# Template register map
Vendor: VendorName Co.Ltd; Series: SeriesName; File version: 1.2
CPU: CM7 r0p1, little endian, MPU, FPU, 4 interrupt priority bits
Registers are 32-bit, read-write, no defined reset value unless marked. A register's access mark holds for its fields unless they carry their own. Offsets are from the block's base; [hi:lo] are bit positions; {n}, {i} and the like mark numbered series; 'fields as' and 'values as' point back to an identical list.

## SYSCON (part 1 of 2) — System Control
Base 0x40037000
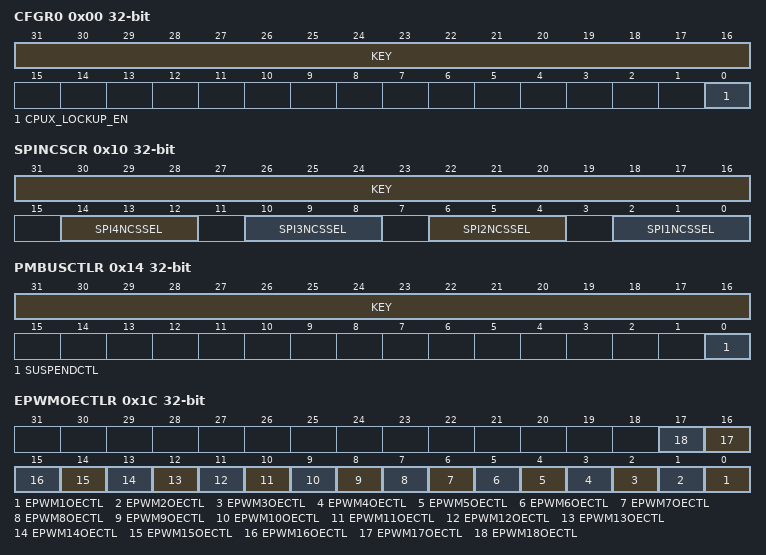
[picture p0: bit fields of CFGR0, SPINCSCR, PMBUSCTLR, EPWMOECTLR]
0x00 CFGR0 — SYSCON CPUx system configuration register 0
  [31:16] KEY wo — SYSCON KEY[15:0] bit: only when 0x5A69 is written can this register be written
  [0] CPUX_LOCKUP_EN — SYSCON CPUX_LOCKUP_EN bit: cortex-M7 CPUx lockup enable bit
0x10 SPINCSCR — SYSCON SPI SSN selection register
  [31:16] KEY wo — SYSCON KEY[15:0] bit: only when 0x5A69 is written can this register be written
  [4n-2:4n-4] SPI{n}NCSSEL (n=1..4) — SYSCON SPI{n}NCSSEL[2:0] bit: SPI{n} NCS signal input source select
0x14 PMBUSCTLR — SYSCON PMBUS control register
  [31:16] KEY wo — SYSCON KEY[15:0] bit: only when 0x5A69 is written at high position can this register be written
  [0] SUSPENDCTL — SYSCON SUSPENDCTL bit: PMBUS suspend control bit
0x1C EPWMOECTLR — SYSCON EPWM output control register
  [n-1] EPWM{n}OECTL (n=1..18) — SYSCON EPWM{n}OECTL bit: EPWM{n} reset output enable control bit
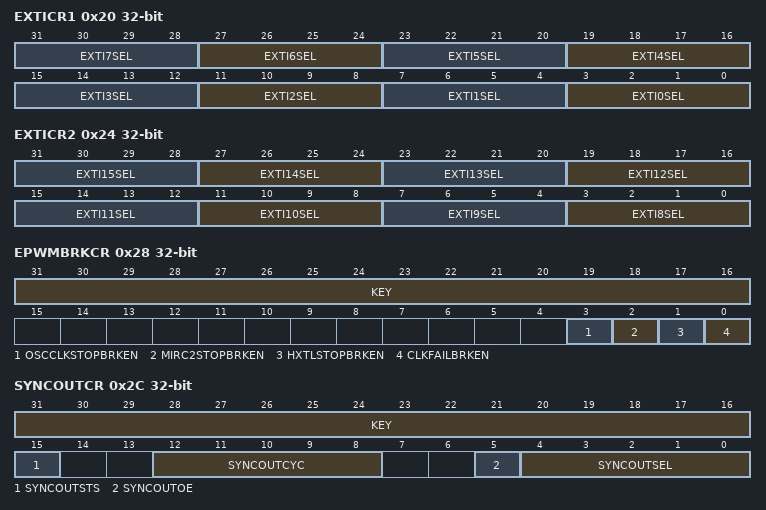
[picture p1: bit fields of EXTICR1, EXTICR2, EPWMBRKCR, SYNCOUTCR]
0x20 EXTICR1 — SYSCON EXTI control register 1
  [4n+3:4n] EXTI{n}SEL (n=0..7) — SYSCON EXTI{n}SEL[3:0] bit: EXTI{n} select
0x24 EXTICR2 — SYSCON EXTI control register 2
  [4n-29:4n-32] EXTI{n}SEL (n=8..15) — SYSCON EXTI{n}SEL[3:0] bit: EXTI{n} select
0x28 EPWMBRKCR — SYSCON EPWM clock fail brake control register
  [31:16] KEY wo — SYSCON KEY[15:0] bit: only when 0x5A69 is written at high position can this register be written
  [3] OSCCLKSTOPBRKEN — SYSCON OSCCLKSTOPBRKEN bit: OSC CLK STOP trigger epwm brake
  [2] MIRC2STOPBRKEN — SYSCON MIRC2STOPBRKEN bit: MIRCPU2 STOP trigger epwm brake
  [1] HXTLSTOPBRKEN — SYSCON HXTLSTOPBRKEN bit: HXTL STOP trigger epwm brake
  [0] CLKFAILBRKEN — SYSCON CLKFAILBRKEN bit: CLKFAIL trigger epwm brake
0x2C SYNCOUTCR — SYSCON SYNCOUT control register
  [31:16] KEY wo — SYSCON KEY[15:0] bit: only when 0x5A69 is written at high position can this register be written
  [15] SYNCOUTSTS ro — SYSCON SYNCOUTSTS bit: SYNCOUT widening status bit
  [12:8] SYNCOUTCYC — SYSCON SYNCOUTCYC[4:0] bit: SYNCOUT widening counting bit
  [5] SYNCOUTOE — SYSCON SYNCOUTOE bit: SYNCOUT output enable
  [4:0] SYNCOUTSEL — SYSCON SYNCOUTSEL[4:0] bit: SYNCOUT select bit
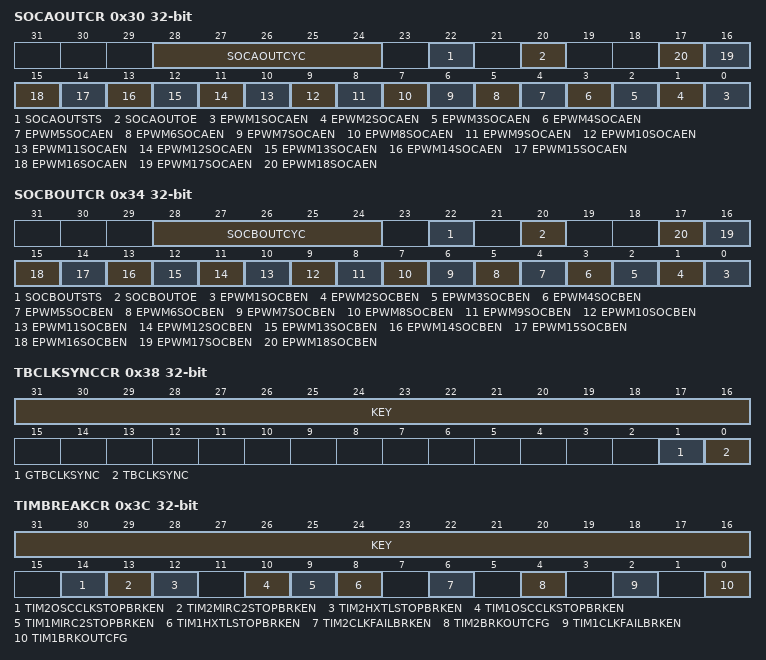
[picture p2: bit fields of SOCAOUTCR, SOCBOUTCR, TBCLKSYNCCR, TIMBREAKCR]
0x30 SOCAOUTCR — SYSCON SOACOUT control register
  [28:24] SOCAOUTCYC — SYSCON SOCAOUTCYC[4:0] bit: SOCAOUT widening counting bit
  [22] SOCAOUTSTS ro — SYSCON SOCAOUTSTS bit: SOCAOUT widening status bit
  [20] SOCAOUTOE — SYSCON SOCAOUTOE bit: ADCSOCA output enable
  [n-1] EPWM{n}SOCAEN (n=1..18) — SYSCON EPWM{n}SOCAEN bit: EPWM{n}SOCA enable bit
0x34 SOCBOUTCR — SYSCON SOCBOUT control register
  [28:24] SOCBOUTCYC — SYSCON SOCBOUTCYC[4:0] bit: SOCBOUT widening counting bit
  [22] SOCBOUTSTS ro — SYSCON SOCBOUTSTS bit: SOCBOUT widening status bit
  [20] SOCBOUTOE — SYSCON SOCBOUTOE bit: ADCSOCB output enable
  [n-1] EPWM{n}SOCBEN (n=1..18) — SYSCON EPWM{n}SOCBEN bit: EPWM{n}SOCB enable bit
0x38 TBCLKSYNCCR — SYSCON CPUx TIMER BASE clock sync control register
  [31:16] KEY wo — SYSCON KEY[15:0] bit: only when 0x5A69 is written at high position can this register be written
  [1] GTBCLKSYNC — SYSCON GTBCLKSYNC bit: global TBCLKSYNC enable bit
  [0] TBCLKSYNC — SYSCON TBCLKSYNC bit: TBCLKSYNC enable bit
0x3C TIMBREAKCR — SYSCON TIM brake control register
  [31:16] KEY wo — SYSCON KEY[15:0] bit: only when 0x5A69 is written at high position can this register be written
  [14] TIM2OSCCLKSTOPBRKEN — SYSCON TIM2OSCCLKSTOPBRKEN bit: OSCCLK STOP triggers TIM2 brake enable bit
  [13] TIM2MIRC2STOPBRKEN — SYSCON TIM2MIRC2STOPBRKEN bit: MIRC2 STOP triggers TIM2 brake enable bit
  [12] TIM2HXTLSTOPBRKEN — SYSCON TIM2HXTLSTOPBRKEN bit: HXTL STOP triggers TIM2 brake enable bit
  [10] TIM1OSCCLKSTOPBRKEN — SYSCON TIM1OSCCLKSTOPBRKEN bit: OSCCLK STOP triggers TIM1 brake enable bit
  [9] TIM1MIRC2STOPBRKEN — SYSCON TIM1MIRC2STOPBRKEN bit: MIRCPU2 STOP triggers TIM1 bake enable bit
  [8] TIM1HXTLSTOPBRKEN — SYSCON TIM1HXTLSTOPBRKEN bit: HXTL STOP triggers TIM1 brake enable bit
  [6] TIM2CLKFAILBRKEN — SYSCON TIM2CLKFAILBRKEN bit: clock fail triggers TIM2 brake enable bit
  [4] TIM2BRKOUTCFG — SYSCON TIM2BRKOUTCFG bit: TIM2 break output enable control bit
  [2] TIM1CLKFAILBRKEN — SYSCON TIM1CLKFAILBRKEN bit: clock fail triggers TIM1 brake enable bit
  [0] TIM1BRKOUTCFG — SYSCON TIM1BRKOUTCFG bit: TIM1 break output enable control bit
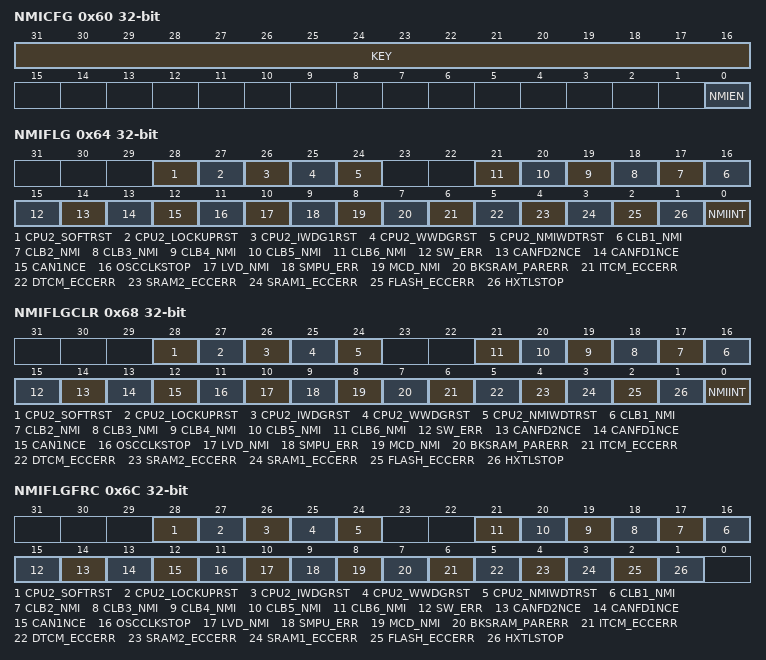
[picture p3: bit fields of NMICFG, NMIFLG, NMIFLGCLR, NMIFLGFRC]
0x60 NMICFG — SYSCON NMI configuration register
  [31:16] KEY wo — SYSCON KEY[15:0] bit: only when 0x5A69 is written at high position can this register be written
  [0] NMIEN — SYSCON NMIEN bit: NMI enable bit
0x64 NMIFLG ro — SYSCON NMI flag register
  [28] CPU2_SOFTRST — SYSCON CPU2_SOFTRST bit: CPU2 SOFT reset flag bit
  [27] CPU2_LOCKUPRST — SYSCON CPU2_LOCKUPRST bit: CPU2 LOCKUP reset flag bit
  [26] CPU2_IWDG1RST — SYSCON CPU2_IWDG1RST bit: CPU2 IWDG1 reset flag bit
  [25] CPU2_WWDGRST — SYSCON CPU2_WWDGRST bit: CPU2 WWDG reset flag bit
  [24] CPU2_NMIWDTRST — SYSCON CPU2_NMIWDTRST bit: CPU2 NMIWDT reset flag bit
  [n+15] CLB{n}_NMI (n=1..6) — SYSCON CLB{n}_NMI bit: CLB{n} NMI flag bit
  [15] SW_ERR — SYSCON SW_ERR bit: SW ERR flag bit
  [14] CANFD2NCE — SYSCON CANFD2NCE bit: CANFD2 NCE flag bit
  [13] CANFD1NCE — SYSCON CANFD1NCE bit: CANFD1 NCE flag bit
  [12] CAN1NCE — SYSCON CAN1NCE bit: CAN1 NCE flag bit
  [11] OSCCLKSTOP — SYSCON OSCCLKSTOP bit: OSCCLK STOP flag bit
  [10] LVD_NMI — SYSCON LVD_NMI bit: LVD NMI flag bit
  [9] SMPU_ERR — SYSCON SMPU_ERR bit: SMPU ECCERR flag bit
  [8] MCD_NMI — SYSCON MCD_NMI bit: MCD NMI flag bit
  [7] BKSRAM_PARERR — SYSCON BKSRAM_PARERR bit: BKSRAM PARERR flag bit
  [6] ITCM_ECCERR — SYSCON ITCM_ECCERR bit: ITCM ECCERR flag bit
  [5] DTCM_ECCERR — SYSCON DTCM_ECCERR bit: DTCM ECCERR flag bit
  [4] SRAM2_ECCERR — SYSCON SRAM2_ECCERR bit: SRAM2 ECCERR flag bit
  [3] SRAM1_ECCERR — SYSCON SRAM1_ECCERR bit: SRAM1 ECCERR flag bit
  [2] FLASH_ECCERR — SYSCON FLASH_ECCERR bit: FLASH ECCERR flag bit
  [1] HXTLSTOP — SYSCON HXTLSTOP bit: HXTL STOP flag bit
  [0] NMIINT — SYSCON NMIINT bit: NMI interrupt flag bit
0x68 NMIFLGCLR — SYSCON NMI flag clear register
  [28] CPU2_SOFTRST — SYSCON CPU2_SOFTRST bit: CPU2 SOFT reset flag clear bit
  [27] CPU2_LOCKUPRST — SYSCON CPU2_LOCKUPRST bit: CPU2 LOCKUP reset flag clear bit
  [26] CPU2_IWDGRST — SYSCON CPU2_IWDGRST bit: CPU2 IWDG reset flag clear bit
  [25] CPU2_WWDGRST — SYSCON CPU2_WWDGRST bit: CPU2 WWDG reset flag clear bit
  [24] CPU2_NMIWDTRST — SYSCON CPU2_NMIWDTRST bit: CPU2 NMIWDT reset flag clear bit
  [n+15] CLB{n}_NMI (n=1..6) — SYSCON CLB{n}_NMI bit: CLB{n} NMI flag clear bit
  [15] SW_ERR — SYSCON SW_ERR bit: SW ERR flag clear bit
  [14] CANFD2NCE — SYSCON CANFD2NCE bit: CANFD2 NCE flag clear bit
  [13] CANFD1NCE — SYSCON CANFD1NCE bit: CANFD1 NCE flag clear bit
  [12] CAN1NCE — SYSCON CAN1NCE bit: CAN1 NCE flag clear bit
  [11] OSCCLKSTOP — SYSCON OSCCLKSTOP bit: OSCCLK STOP flag clear bit
  [10] LVD_NMI — SYSCON LVD_NMI bit: LVD NMI flag clear bit
  [9] SMPU_ERR — SYSCON SMPU_ERR bit: SMPU ECCERR flag clear bit
  [8] MCD_NMI — SYSCON MCD_NMI bit: MCD NMI flag clear bit
  [7] BKSRAM_PARERR — SYSCON BKSRAM_PARERR bit: BKSRAM PARERR flag clear bit
  [6] ITCM_ECCERR — SYSCON ITCM_ECCERR bit: ITCM ECCERR flag clear bit
  [5] DTCM_ECCERR — SYSCON DTCM_ECCERR bit: DTCM ECCERR flag clear bit
  [4] SRAM2_ECCERR — SYSCON SRAM2_ECCERR bit: SRAM2 ECCERR flag clear bit
  [3] SRAM1_ECCERR — SYSCON SRAM1_ECCERR bit: SRAM1 ECCERR flag clear bit
  [2] FLASH_ECCERR — SYSCON FLASH_ECCERR bit: FLASH ECCERR flag clear bit
  [1] HXTLSTOP — SYSCON HXTLSTOP bit: HXTL STOP flag clear bit
  [0] NMIINT — SYSCON NMIINT bit: NMI interrupt flag clear bit
0x6C NMIFLGFRC — SYSCON NMI flag force register
  [28] CPU2_SOFTRST — SYSCON CPU2_SOFTRST bit: CPU2 SOFT reset flag force bit
  [27] CPU2_LOCKUPRST — SYSCON CPU2_LOCKUPRST bit: CPU2 LOCKUP reset flag force bit
  [26] CPU2_IWDGRST — SYSCON CPU2_IWDGRST bit: CPU2 IWDG reset flag force bit
  [25] CPU2_WWDGRST — SYSCON CPU2_WWDGRST bit: CPU2 WWDG reset flag force bit
  [24] CPU2_NMIWDTRST — SYSCON CPU2_NMIWDTRST bit: CPU2 NMIWDT reset flag force bit
  [n+15] CLB{n}_NMI (n=1..6) — SYSCON CLB{n}_NMI bit: CLB{n} NMI flag force bit
  [15] SW_ERR — SYSCON SW_ERR bit: SW ERR flag force bit
  [14] CANFD2NCE — SYSCON CANFD2NCE bit: CANFD2 NCE flag force bit
  [13] CANFD1NCE — SYSCON CANFD1NCE bit: CANFD1 NCE flag force bit
  [12] CAN1NCE — SYSCON CAN1NCE bit: CAN1 NCE flag force bit
  [11] OSCCLKSTOP — SYSCON OSCCLKSTOP bit: OSCCLK STOP flag force bit
  [10] LVD_NMI — SYSCON LVD_NMI bit: LVD NMI flag force bit
  [9] SMPU_ERR — SYSCON SMPU_ERR bit: SMPU ECCERR flag force bit
  [8] MCD_NMI — SYSCON MCD_NMI bit: MCD NMI flag force bit
  [7] BKSRAM_PARERR — SYSCON BKSRAM_PARERR bit: BKSRAM PARERR flag force bit
  [6] ITCM_ECCERR — SYSCON ITCM_ECCERR bit: ITCM ECCERR flag force bit
  [5] DTCM_ECCERR — SYSCON DTCM_ECCERR bit: DTCM ECCERR flag force bit
  [4] SRAM2_ECCERR — SYSCON SRAM2_ECCERR bit: SRAM2 ECCERR flag force bit
  [3] SRAM1_ECCERR — SYSCON SRAM1_ECCERR bit: SRAM1 ECCERR flag force bit
  [2] FLASH_ECCERR — SYSCON FLASH_ECCERR bit: FLASH ECCERR flag force bit
  [1] HXTLSTOP — SYSCON HXTLSTOP bit: HXTL STOP flag force bit
0x70 NMIWDGCNT ro — SYSCON NMIWDG counter register
  [15:0] NMIWDGCNT — SYSCON NMIWDGCNT[15:0] bit: NMIWDG counter
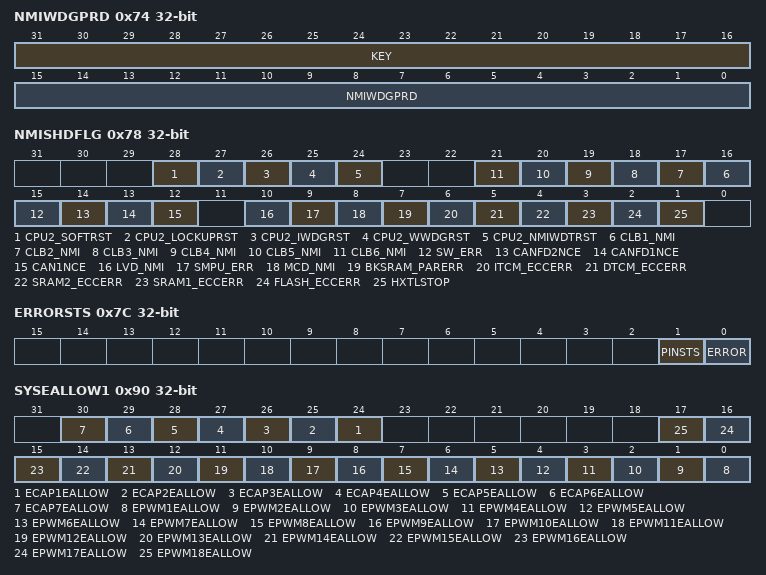
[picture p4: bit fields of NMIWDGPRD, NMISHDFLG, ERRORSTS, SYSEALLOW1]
0x74 NMIWDGPRD — SYSCON NMIWDG period register
  [31:16] KEY wo — SYSCON KEY[15:0] bit: only when 0x5A69 is written at high position can this register be written
  [15:0] NMIWDGPRD — SYSCON NMIWDGPRD[15:0] bit: NMIWDG period
0x78 NMISHDFLG ro — SYSCON NMI shadow flag register
  [28] CPU2_SOFTRST — SYSCON CPU2_SOFTRST bit: CPU2 SOFT reset shadow flag bit
  [27] CPU2_LOCKUPRST — SYSCON CPU2_LOCKUPRST bit: CPU2 LOCKUP reset shadow flag bit
  [26] CPU2_IWDGRST — SYSCON CPU2_IWDGRST bit: CPU2 IWDG reset shadow flag bit
  [25] CPU2_WWDGRST — SYSCON CPU2_WWDGRST bit: CPU2 WWDG reset shadow flag bit
  [24] CPU2_NMIWDTRST — SYSCON CPU2_NMIWDTRST bit: CPU2 NMIWDT reset shadow flag bit
  [n+15] CLB{n}_NMI (n=1..6) — SYSCON CLB{n}_NMI bit: CLB{n} NMI shadow flag bit
  [15] SW_ERR — SYSCON SW_ERR bit: SW ERR shadow flag bit
  [14] CANFD2NCE — SYSCON CANFD2NCE bit: CANFD2 NCE shadow flag bit
  [13] CANFD1NCE — SYSCON CANFD1NCE bit: CANFD1 NCE shadow flag bit
  [12] CAN1NCE — SYSCON CAN1NCE bit: CAN1 NCE shadow flag bit
  [10] LVD_NMI — SYSCON LVD_NMI bit: LVD NMI shadow flag bit
  [9] SMPU_ERR — SYSCON SMPU_ERR bit: SMPU ECCERR shadow flag bit
  [8] MCD_NMI — SYSCON MCD_NMI bit: MCD NMI shadow flag bit
  [7] BKSRAM_PARERR — SYSCON BKSRAM_PARERR bit: BKSRAM PARERR shadow flag bit
  [6] ITCM_ECCERR — SYSCON ITCM_ECCERR bit: ITCM ECCERR shadow flag bit
  [5] DTCM_ECCERR — SYSCON DTCM_ECCERR bit: DTCM ECCERR shadow flag bit
  [4] SRAM2_ECCERR — SYSCON SRAM2_ECCERR bit: SRAM2 ECCERR shadow flag bit
  [3] SRAM1_ECCERR — SYSCON SRAM1_ECCERR bit: SRAM1 ECCERR shadow flag bit
  [2] FLASH_ECCERR — SYSCON FLASH_ECCERR bit: FLASH ECCERR shadow flag bit
  [1] HXTLSTOP — SYSCON HXTLSTOP bit: HXTL STOP shadow flag bit
0x7C ERRORSTS ro — SYSCON error status register
  [1] PINSTS — SYSCON PINSTS bit: ERROR pin status bit
  [0] ERROR — SYSCON ERROR bit: ERROR status bit
0x80 ERRORSTSCLR — SYSCON error status clear register
  [0] ERROR — SYSCON ERROR bit: ERROR status clear bit
0x84 ERRORSTSFRC — SYSCON error status force register
  [0] ERROR — SYSCON ERROR bit: ERROR status force bit
0x88 ERRORCTL — SYSCON error status control register
  [0] ERRORPOL — SYSCON ERRORPOL bit: ERROR polarity select bit
0x8C ERRORLOCK — SYSCON error status lock register
  [0] ERRORCTL — SYSCON ERRORCTL bit: ERRORCTL register lock bit
0x90 SYSEALLOW1 — SYSCON system EALLOW register 1
  [n+23] ECAP{n}EALLOW (n=1..7) — SYSCON ECAP{n}EALLOW bit: ECAP{n} EALLOW write enable bit
  [n-1] EPWM{n}EALLOW (n=1..18) — SYSCON EPWM{n}EALLOW bit: EPWM{n} EALLOW write enable bit
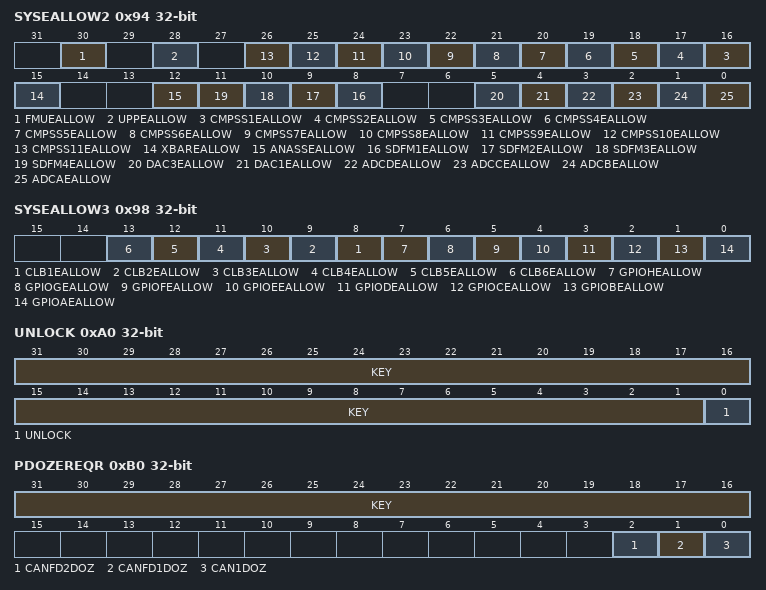
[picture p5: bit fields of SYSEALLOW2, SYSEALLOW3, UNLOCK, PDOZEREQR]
0x94 SYSEALLOW2 — SYSCON system EALLOW register 2
  [30] FMUEALLOW — SYSCON FMUEALLOW bit: FMU EALLOW write enable bit
  [28] UPPEALLOW — SYSCON UPPEALLOW bit: UPP EALLOW write enable bit
  [n+15] CMPSS{n}EALLOW (n=1..11) — SYSCON CMPSS{n}EALLOW bit: CMPSS{n} EALLOW write enable bit
  [15] XBAREALLOW — SYSCON XBAREALLOW bit: XBAR EALLOW write enable bit
  [12] ANASSEALLOW — SYSCON ANASSEALLOW bit: ANASS EALLOW write enable bit
  [n+7] SDFM{n}EALLOW (n=1..4) — SYSCON SDFM{n}EALLOW bit: SDFM{n} EALLOW write enable bit
  [5] DAC3EALLOW — SYSCON DAC3EALLOW bit: DAC3 EALLOW write enable bit
  [4] DAC1EALLOW — SYSCON DAC1EALLOW bit: DAC1 EALLOW write enable bit
  [3] ADCDEALLOW — SYSCON ADCDEALLOW bit: ADCD EALLOW write enable bit
  [2] ADCCEALLOW — SYSCON ADCCEALLOW bit: ADCC EALLOW write enable bit
  [1] ADCBEALLOW — SYSCON ADCBEALLOW bit: ADCB EALLOW write enable bit
  [0] ADCAEALLOW — SYSCON ADCAEALLOW bit: ADCA EALLOW write enable bit
0x98 SYSEALLOW3 — SYSCON system EALLOW register 3
  [n+7] CLB{n}EALLOW (n=1..6) — SYSCON CLB{n}EALLOW bit: CLB{n} EALLOW write enable bit
  [7] GPIOHEALLOW — SYSCON GPIOHEALLOW bit: GPIOH EALLOW write enable bit
  [6] GPIOGEALLOW — SYSCON GPIOGEALLOW bit: GPIOG EALLOW write enable bit
  [5] GPIOFEALLOW — SYSCON GPIOFEALLOW bit: GPIOF EALLOW write enable bit
  [4] GPIOEEALLOW — SYSCON GPIOEEALLOW bit: GPIOE EALLOW write enable bit
  [3] GPIODEALLOW — SYSCON GPIODEALLOW bit: GPIOD EALLOW write enable bit
  [2] GPIOCEALLOW — SYSCON GPIOCEALLOW bit: GPIOC EALLOW write enable bit
  [1] GPIOBEALLOW — SYSCON GPIOBEALLOW bit: GPIOB EALLOW write enable bit
  [0] GPIOAEALLOW — SYSCON GPIOAEALLOW bit: GPIOA EALLOW write enable bit
0xA0 UNLOCK — SYSCON lock bit for SYSCON register
  [31:1] KEY wo — SYSCON KEY[30:0] bit: only when 0x2AD5334C is written at high position can this register be written
  [0] UNLOCK — SYSCON UNLOCK bit: unlock protection enable bit
0xB0 PDOZEREQR — SYSCON peripheral module DOZE mode request register
  [31:16] KEY wo — SYSCON KEY[15:0] bit: only when 0x5A69 is written at high position can this register be written
  [2] CANFD2DOZ — SYSCON CANFD2DOZ bit: CANFD2 DOZE request
  [1] CANFD1DOZ — SYSCON CANFD1DOZ bit: CANFD1 DOZE request
  [0] CAN1DOZ — SYSCON CAN1DOZ bit: CAN1 DOZE request
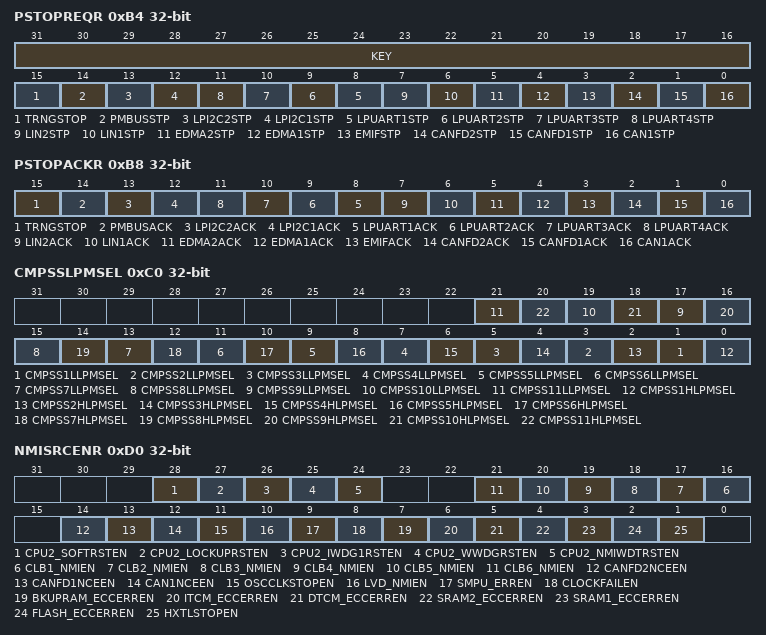
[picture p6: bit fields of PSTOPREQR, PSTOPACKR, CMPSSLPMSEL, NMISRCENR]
0xB4 PSTOPREQR — SYSCON peripheral module STOP mode request register
  [31:16] KEY wo — SYSCON KEY[15:0] bit: only when 0x5A69 is written at high position can this register be written
  [15] TRNGSTOP — SYSCON TRNGSTOP bit: TRNG STOP request
  [14] PMBUSSTP — SYSCON PMBUSSTP bit: PMBUS STOP request
  [13] LPI2C2STP — SYSCON LPI2C2STP bit: LPI2C2 STOP request
  [12] LPI2C1STP — SYSCON LPI2C1STP bit: LPI2C1 STOP request
  [n+7] LPUART{n}STP (n=1..4) — SYSCON LPUART{n}STP bit: LPUART{n} STOP request
  [7] LIN2STP — SYSCON LIN2STP bit: LIN2 STOP request
  [6] LIN1STP — SYSCON LIN1STP bit: LIN1 STOP request
  [5] EDMA2STP — SYSCON EDMA2STP bit: EDMA2 STOP request
  [4] EDMA1STP — SYSCON EDMA1STP bit: EDMA1 STOP request
  [3] EMIFSTP — SYSCON EMIFSTP bit: EMIF STOP request
  [2] CANFD2STP — SYSCON CANFD2STP bit: CANFD2 STOP request
  [1] CANFD1STP — SYSCON CANFD1STP bit: CANFD1 STOP request
  [0] CAN1STP — SYSCON CAN1STP bit: CAN1 STOP request
0xB8 PSTOPACKR ro — SYSCON peripheral module STOP mode acknowledge register
  [15] TRNGSTOP — SYSCON TRNGSTOP bit: TRNG STOP acknowledge bit
  [14] PMBUSACK — SYSCON PMBUSACK bit: PMBUS STOP acknowledge bit
  [13] LPI2C2ACK — SYSCON LPI2C2ACK bit: LPI2C2 STOP acknowledge bit
  [12] LPI2C1ACK — SYSCON LPI2C1ACK bit: LPI2C1 STOP acknowledge bit
  [n+7] LPUART{n}ACK (n=1..4) — SYSCON LPUART{n}ACK bit: LPUART{n} STOP acknowledge bit
  [7] LIN2ACK — SYSCON LIN2ACK bit: LIN2 STOP acknowledge bit
  [6] LIN1ACK — SYSCON LIN1ACK bit: LIN1 STOP acknowledge bit
  [5] EDMA2ACK — SYSCON EDMA2ACK bit: EDMA2 STOP acknowledge bit
  [4] EDMA1ACK — SYSCON EDMA1ACK bit: EDMA1 STOP acknowledge bit
  [3] EMIFACK — SYSCON EMIFACK bit: EMIF STOP acknowledge bit
  [2] CANFD2ACK — SYSCON CANFD2ACK bit: CANFD2 STOP acknowledge bit
  [1] CANFD1ACK — SYSCON CANFD1ACK bit: CANFD1 STOP acknowledge bit
  [0] CAN1ACK — SYSCON CAN1ACK bit: CAN1 STOP acknowledge bit
0xC0 CMPSSLPMSEL — SYSCON CMPSS low power mode wake up selecting register
  [2n-1] CMPSS{n}LLPMSEL (n=1..11) — SYSCON CMPSS{n}LLPMSEL bit: CMPSS{n}L and low power wake up and interruption circuit connection select
  [2n-2] CMPSS{n}HLPMSEL (n=1..11) — SYSCON CMPSS{n}HLPMSEL bit: CMPSS{n}H and low power wake up and interruption circuit connection select
0xD0 NMISRCENR — SYSCON NMI source enable register
  [28] CPU2_SOFTRSTEN — SYSCON CPU2_SOFTRSTEN bit: CPU2 SOFT reset enable bit
  [27] CPU2_LOCKUPRSTEN — SYSCON CPU2_LOCKUPRSTEN bit: CPU2 LOCKUP reset enable bit
  [26] CPU2_IWDG1RSTEN — SYSCON CPU2_IWDG1RSTEN bit: CPU2 IWDG1 reset enable bit
  [25] CPU2_WWDGRSTEN — SYSCON CPU2_WWDGRSTEN bit: CPU2 WWDG reset enable bit
  [24] CPU2_NMIWDTRSTEN — SYSCON CPU2_NMIWDTRSTEN bit: CPU2 NMIWDT reset enable bit
  [n+15] CLB{n}_NMIEN (n=1..6) — SYSCON CLB{n}_NMIEN bit: CLB{n} NMI enable bit
  [14] CANFD2NCEEN — SYSCON CANFD2NCEEN bit: CANFD2 NCE enable bit
  [13] CANFD1NCEEN — SYSCON CANFD1NCEEN bit: CANFD1 NCE enable bit
  [12] CAN1NCEEN — SYSCON CAN1NCEEN bit: CAN1 NCE enable bit
  [11] OSCCLKSTOPEN — SYSCON OSCCLKSTOPEN bit: OSCCLK STOP enable bit
  [10] LVD_NMIEN — SYSCON LVD_NMIEN bit: LVD NMI enable bit
  [9] SMPU_ERREN — SYSCON SMPU_ERREN bit: SMPU ECCERR enable bit
  [8] CLOCKFAILEN — SYSCON CLOCKFAILEN bit: CLOCKFAIL enable bit
  [7] BKUPRAM_ECCERREN — SYSCON BKUPRAM_ECCERREN bit: BKUPRAM ECCERR enable bit
  [6] ITCM_ECCERREN — SYSCON ITCM_ECCERREN bit: ITCM ECCERR enable bit
  [5] DTCM_ECCERREN — SYSCON DTCM_ECCERREN bit: DTCM ECCERR enable bit
  [4] SRAM2_ECCERREN — SYSCON SRAM2_ECCERREN bit: SRAM2 ECCERR enable bit
  [3] SRAM1_ECCERREN — SYSCON SRAM1_ECCERREN bit: SRAM1 ECCERR enable bit
  [2] FLASH_ECCERREN — SYSCON FLASH_ECCERREN bit: Flash ECCERR enable bit
  [1] HXTLSTOPEN — SYSCON HXTLSTOPEN bit: HXTL STOP enable bit
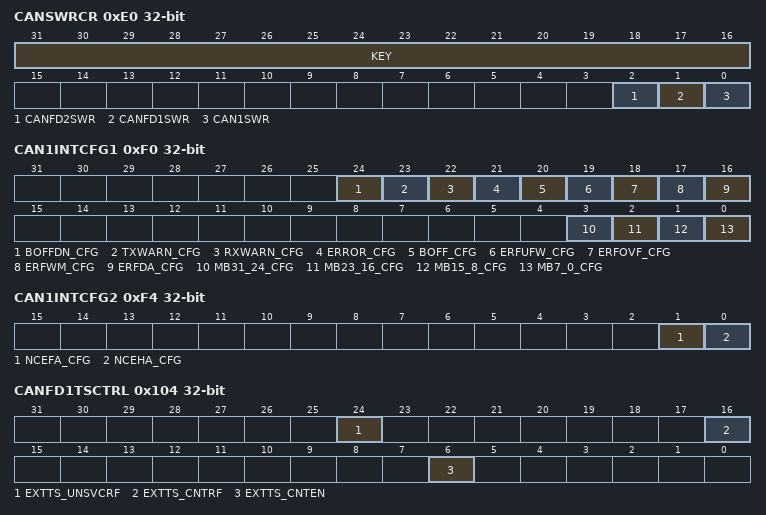
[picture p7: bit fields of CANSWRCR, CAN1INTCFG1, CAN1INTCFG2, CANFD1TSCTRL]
0xE0 CANSWRCR — SYSCON CAN software reset control register
  [31:16] KEY wo — SYSCON KEY[15:0] bit: only when 0x5A69 is written at high position can this register be written
  [2] CANFD2SWR — SYSCON CANFD2SWR bit: CANFD2 software reset
  [1] CANFD1SWR — SYSCON CANFD1SWR bit: CANFD1 software reset
  [0] CAN1SWR — SYSCON CAN1SWR bit: CAN1 software reset
0xF0 CAN1INTCFG1 — SYSCON CAN1 interrupt configuration register 1
  [24] BOFFDN_CFG — SYSCON BOFFDN_CFG bit: BUS OFF DONE interrupt configuration bit
  [23] TXWARN_CFG — SYSCON TXWARN_CFG bit: TX WARNING interrupt configuration bit
  [22] RXWARN_CFG — SYSCON RXWARN_CFG bit: RX WARNING interrupt configuration bit
  [21] ERROR_CFG — SYSCON ERROR_CFG bit: ERROR interrupt configuration bit
  [20] BOFF_CFG — SYSCON BOFF_CFG bit: BUS OFF interrupt configuration bit
  [19] ERFUFW_CFG — SYSCON ERFUFW_CFG bit: ERFUFW interrupt configuration bit
  [18] ERFOVF_CFG — SYSCON ERFOVF_CFG bit: ERFOVF interrupt configuration bit
  [17] ERFWM_CFG — SYSCON ERFWM_CFG bit: ERFWM interrupt configuration bit
  [16] ERFDA_CFG — SYSCON ERFDA_CFG bit: ERFDA interrupt configuration bit
  [3] MB31_24_CFG — SYSCON MB31_24_CFG bit: MB 31~24 interrupt configuration bit
  [2] MB23_16_CFG — SYSCON MB23_16_CFG bit: MB 23~16 interrupt configuration bit
  [1] MB15_8_CFG — SYSCON MB15_8_CFG bit: MB 15~8 interrupt configuration bit
  [0] MB7_0_CFG — SYSCON MB7_0_CFG bit: MB 7~0 interrupt configuration bit
0xF4 CAN1INTCFG2 — SYSCON CAN1 interrupt configuration register 2
  [1] NCEFA_CFG — SYSCON NCEFA_CFG bit: NCEFA interrupt configuration bit
  [0] NCEHA_CFG — SYSCON NCEHA_CFG bit: NCEHA interrupt configuration bit
0x104 CANFD1TSCTRL — SYSCON CANFD1 timestamp control register
  [24] EXTTS_UNSVCRF — SYSCON EXTTS_UNSVCRF bit: external timestamp count overflow interruption counting
  [16] EXTTS_CNTRF — SYSCON EXTTS_CNTRF bit: external timestamp counting clear bit
  [6] EXTTS_CNTEN — SYSCON EXTTS_CNTEN bit: external timestamp counting enable bit
0x10C CANFD1TSICR — SYSCON CANFD1 timestamp interruption clear register
  [0] EXTTS_OVFIC — SYSCON EXTTS_OVFIC bit: external timestamp overflow interruption clear bit
0x110 CANFD1TSIFR ro — SYSCON CANFD1 timestamp interruption flag register
  [0] EXTTS_OVFIF — SYSCON EXTTS_OVFIF bit: external timestamp overflow interruption flag bit
0x118 CANFD1TSIER — SYSCON CANFD1 timestamp interruption enable register
  [0] EXTTS_OVFIE — SYSCON EXTTS_OVFIE bit: external timestamp overflow interruption enable bit
0x124 CANFD1TSPRESC — SYSCON CANFD1 timestamp prescale register
  [23:0] EXTTS_PRESC — SYSCON EXTTS_PRESC[23:0] bit: external timestamp prescale counter
0x128 CANFD1TSUNSVCIC ro — SYSCON CANFD1 timestamp zero interruption counter register
  [4:0] EXTTS_UNSVC — SYSCON EXTTS_UNSVC[4:0] bit: external timestamp overflow interruption counter
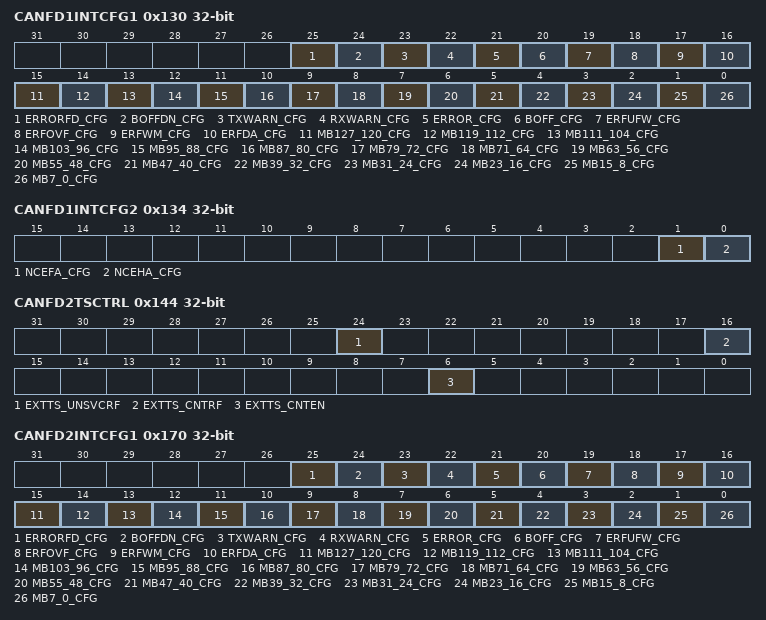
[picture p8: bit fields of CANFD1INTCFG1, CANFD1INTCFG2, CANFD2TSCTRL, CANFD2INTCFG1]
0x130 CANFD1INTCFG1 — SYSCON CANFD1 interrupt configuration register 1
  [25] ERRORFD_CFG — SYSCON ERRORFD_CFG bit: ERROR FD interrupt configuration bit
  [24] BOFFDN_CFG — SYSCON BOFFDN_CFG bit: BUS OFF DONE interrupt configuration bit
  [23] TXWARN_CFG — SYSCON TXWARN_CFG bit: TX WARNING interrupt configuration bit
  [22] RXWARN_CFG — SYSCON RXWARN_CFG bit: RX WARNING interrupt configuration bit
  [21] ERROR_CFG — SYSCON ERROR_CFG bit: ERROR interrupt configuration bit
  [20] BOFF_CFG — SYSCON BOFF_CFG bit: BUS OFF interrupt configuration bit
  [19] ERFUFW_CFG — SYSCON ERFUFW_CFG bit: ERFUFW interrupt configuration bit
  [18] ERFOVF_CFG — SYSCON ERFOVF_CFG bit: ERFOVF interrupt configuration bit
  [17] ERFWM_CFG — SYSCON ERFWM_CFG bit: ERFWM interrupt configuration bit
  [16] ERFDA_CFG — SYSCON ERFDA_CFG bit: ERFDA interrupt configuration bit
  [15] MB127_120_CFG — SYSCON MB127_120_CFG bit: MB 127~120 interrupt configuration bit
  [14] MB119_112_CFG — SYSCON MB119_112_CFG bit: MB 119~112 interrupt configuration bit
  [13] MB111_104_CFG — SYSCON MB111_104_CFG bit: MB 111~104 interrupt configuration bit
  [12] MB103_96_CFG — SYSCON MB103_96_CFG bit: MB 103~96 interrupt configuration bit
  [11] MB95_88_CFG — SYSCON MB95_88_CFG bit: MB 95~88 interrupt configuration bit
  [10] MB87_80_CFG — SYSCON MB87_80_CFG bit: MB 87~80 interrupt configuration bit
  [9] MB79_72_CFG — SYSCON MB79_72_CFG bit: MB 79~72 interrupt configuration bit
  [8] MB71_64_CFG — SYSCON MB71_64_CFG bit: MB 71~64 interrupt configuration bit
  [7] MB63_56_CFG — SYSCON MB63_56_CFG bit: MB 63~56 interrupt configuration bit
  [6] MB55_48_CFG — SYSCON MB55_48_CFG bit: MB 55~48 interrupt configuration bit
  [5] MB47_40_CFG — SYSCON MB47_40_CFG bit: MB 47~40 interrupt configuration bit
  [4] MB39_32_CFG — SYSCON MB39_32_CFG bit: MB 39~32 interrupt configuration bit
  [3] MB31_24_CFG — SYSCON MB31_24_CFG bit: MB 31~24 interrupt configuration bit
  [2] MB23_16_CFG — SYSCON MB23_16_CFG bit: MB 23~16 interrupt configuration bit
  [1] MB15_8_CFG — SYSCON MB15_8_CFG bit: MB 15~8 interrupt configuration bit
  [0] MB7_0_CFG — SYSCON MB7_0_CFG bit: MB 7~0 interrupt configuration bit
0x134 CANFD1INTCFG2 — SYSCON CANFD1 interrupt configuration register 2
  fields as CAN1INTCFG2
0x144 CANFD2TSCTRL — SYSCON CANFD2 timestamp control register
  fields as CANFD1TSCTRL
0x14C CANFD2TSICR — SYSCON CANFD2 timestamp interruption clear register
  fields as CANFD1TSICR
0x150 CANFD2TSIFR — SYSCON CANFD2 timestamp interruption flag register
  fields as CANFD1TSIFR
0x158 CANFD2TSIER — SYSCON CANFD2 timestamp interruption enable register
  fields as CANFD1TSIER
0x164 CANFD2TSPRESC — SYSCON CANFD2 timestamp prescale register
  fields as CANFD1TSPRESC
0x168 CANFD2TSUNSVCIC — SYSCON CANFD2 timestamp register
  fields as CANFD1TSUNSVCIC
0x170 CANFD2INTCFG1 — SYSCON CANFD2 interrupt configuration register 1
  fields as CANFD1INTCFG1
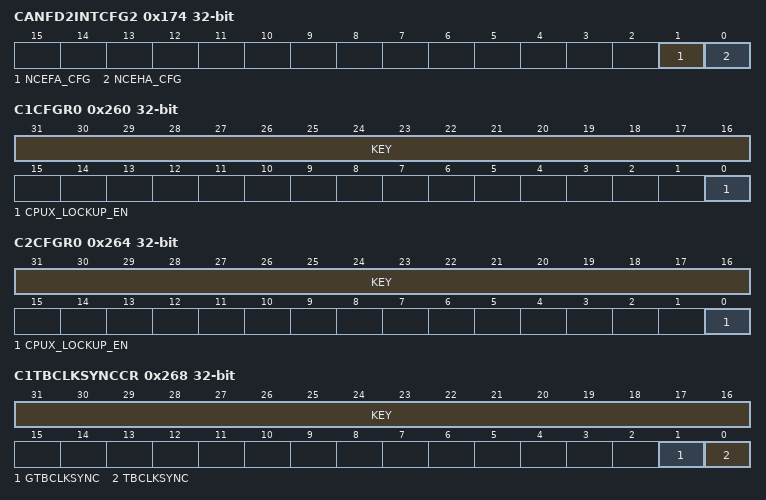
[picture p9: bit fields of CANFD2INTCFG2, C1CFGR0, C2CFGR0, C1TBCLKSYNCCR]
0x174 CANFD2INTCFG2 — SYSCON CANFD2 interrupt configuration register 2
  fields as CAN1INTCFG2
{0x1BC+4i} DMAMUX1REN{i} (i=1..4) — SYSCON DMAMUX1 request enable register {i}
  [31:0] DMAMUX1REN{i} — SYSCON DMAMUX1REN{i}[31:0] bit: DMAMUX1 number{32i-1}~{32i-32} request enable bit
0x1D0 DMAMUX1REN5 — SYSCON DMAMUX1 request enable register 5
  [13:0] DMAMUX1REN5 — SYSCON DMAMUX1REN5[13:0] bit: DMAMUX1 number141~128 request enable bit
{0x1DC+4i} DMAMUX2REN{i} (i=1..4) — SYSCON DMAMUX2 request enable register {i}
  [31:0] DMAMUX2REN{i} — SYSCON DMAMUX2REN{i}[31:0] bit: DMAMUX2 number{32i-1}~{32i-32} request enable bit
0x1F0 DMAMUX2REN5 — SYSCON DMAMUX2 request enable register 5
  [13:0] DMAMUX2REN5 — SYSCON DMAMUX2REN5[13:0] bit: DMAMUX2 number141~128 request enable bit
{0x1FC+4i} INTEN{i} (i=1..8) — SYSCON interrupt enable register {i}
  [31:0] INTEN{i} — SYSCON INTEN{i}[31:0] bit: number{32i-1}~{32i-32} interrupt enable bit
{0x21C+4i} C1INTEN{i} ro (i=1..8) — SYSCON CPU1 interrupt enable read only register {i}
  [31:0] INTEN{i} — SYSCON INTEN{i}[31:0] bit: CPU1 number{32i-1}~{32i-32} interrupt enable bit
{0x23C+4i} C2INTEN{i} ro (i=1..8) — SYSCON CPU2 interrupt enable read only register {i}
  [31:0] INTEN{i} — SYSCON INTEN{i}[31:0] bit: CPU2 number{32i-1}~{32i-32} interrupt enable bit
0x260 C1CFGR0 — SYSCON CPU1 system configuration read only register 0
  [31:16] KEY wo — SYSCON KEY[15:0] bit: only when 0x5A69 is written at high position can this register be written
  [0] CPUX_LOCKUP_EN ro — SYSCON CPUX_LOCKUP_EN bit: cortex-M7 CPU1 lockup function enable
0x264 C2CFGR0 — SYSCON CPU2 system configuration read only register 0
  [31:16] KEY wo — SYSCON KEY[15:0] bit: only when 0x5A69 is written at high position can this register be written
  [0] CPUX_LOCKUP_EN ro — SYSCON CPUX_LOCKUP_EN bit: cortex-M7 CPU2 lockup function enable
0x268 C1TBCLKSYNCCR — SYSCON CPU1 TIMER BASE clock sync control read only register
  [31:16] KEY wo — SYSCON KEY[15:0] bit: only when 0x5A69 is written at high position can this register be written
  [1] GTBCLKSYNC ro — SYSCON GTBCLKSYNC bit: CPU1 global TBCLKSYNC enable bit
  [0] TBCLKSYNC ro — SYSCON TBCLKSYNC bit: CPU1 TBCLKSYNC enable bit
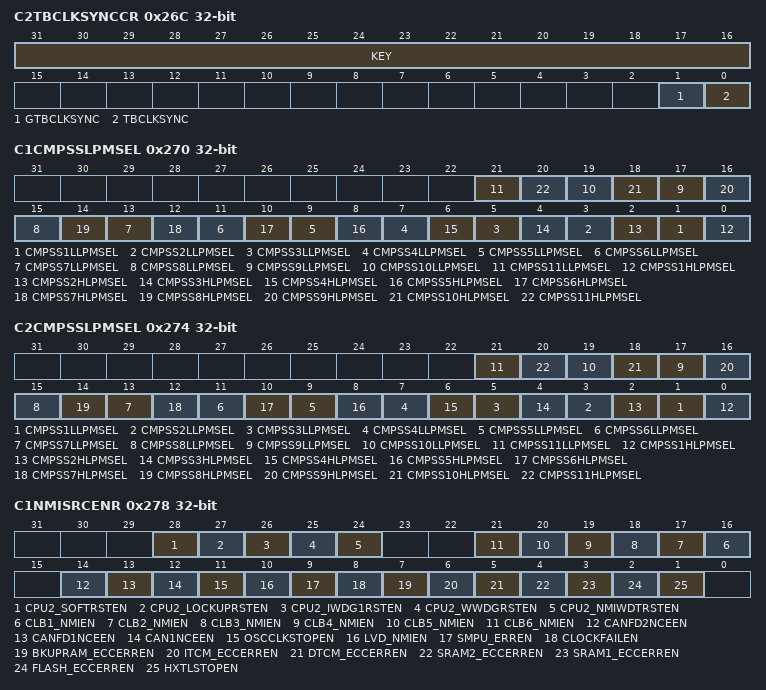
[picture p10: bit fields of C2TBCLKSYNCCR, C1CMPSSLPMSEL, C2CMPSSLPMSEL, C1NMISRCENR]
0x26C C2TBCLKSYNCCR — SYSCON CPU2 TIMER BASE clock sync control read only register
  [31:16] KEY wo — SYSCON KEY[15:0] bit: only when 0x5A69 is written at high position can this register be written
  [1] GTBCLKSYNC ro — SYSCON GTBCLKSYNC bit: CPU2 global TBCLKSYNC enable bit
  [0] TBCLKSYNC ro — SYSCON TBCLKSYNC bit: CPU2 TBCLKSYNC enable bit
0x270 C1CMPSSLPMSEL ro — SYSCON CPU1 CMPSS low power mode wake up or interrupt selecting read only register
  [2n-1] CMPSS{n}LLPMSEL (n=1..11) — SYSCON CMPSS{n}LLPMSEL bit: CPU1 CMPSS{n}L and low power wake up and interruption circuit connection select
  [2n-2] CMPSS{n}HLPMSEL (n=1..11) — SYSCON CMPSS{n}HLPMSEL bit: CPU1 CMPSS{n}H and low power wake up and interruption circuit connection select
0x274 C2CMPSSLPMSEL ro — SYSCON CPU2 CMPSS low power mode wake up or interrupt selecting read only register
  [2n-1] CMPSS{n}LLPMSEL (n=1..11) — SYSCON CMPSS{n}LLPMSEL bit: CPU2 CMPSS{n}L and low power wake up and interruption circuit connection select
  [2n-2] CMPSS{n}HLPMSEL (n=1..11) — SYSCON CMPSS{n}HLPMSEL bit: CPU2 CMPSS{n}H and low power wake up and interruption circuit connection select
0x278 C1NMISRCENR ro — SYSCON CPU1 NMI source enable read only register
  [28] CPU2_SOFTRSTEN — SYSCON CPU2_SOFTRSTEN bit: CPU2 SOFT reset enable bit of CPU1
  [27] CPU2_LOCKUPRSTEN — SYSCON CPU2_LOCKUPRSTEN bit: CPU2 LOCKUP reset enable bit of CPU1
  [26] CPU2_IWDG1RSTEN — SYSCON CPU2_IWDG1RSTEN bit: CPU2 IWDG1 reset enable bit of CPU1
  [25] CPU2_WWDGRSTEN — SYSCON CPU2_WWDGRSTEN bit: CPU2 WWDG reset enable bit of CPU1
  [24] CPU2_NMIWDTRSTEN — SYSCON CPU2_NMIWDTRSTEN bit: CPU2 NMIWDT reset enable bit of CPU1
  [n+15] CLB{n}_NMIEN (n=1..6) — SYSCON CLB{n}_NMIEN bit: CLB{n} NMI enable bit of CPU1
  [14] CANFD2NCEEN — SYSCON CANFD2NCEEN bit: CANFD2 NCE enable bit of CPU1
  [13] CANFD1NCEEN — SYSCON CANFD1NCEEN bit: CANFD1 NCE enable bit of CPU1
  [12] CAN1NCEEN — SYSCON CAN1NCEEN bit: CAN1 NCE enable bit of CPU1
  [11] OSCCLKSTOPEN — SYSCON OSCCLKSTOPEN bit: OSCCLK STOP enable bit of CPU1
  [10] LVD_NMIEN — SYSCON LVD_NMIEN bit: LVD NMI enable bit of CPU1
  [9] SMPU_ERREN — SYSCON SMPU_ERREN bit: SMPU ECCERR enable bit of CPU1
  [8] CLOCKFAILEN — SYSCON CLOCKFAILEN bit: CLOCKFAIL enable bit of CPU1
  [7] BKUPRAM_ECCERREN — SYSCON BKUPRAM_ECCERREN bit: BKUPRAM ECCERR enable bit of CPU1
  [6] ITCM_ECCERREN — SYSCON ITCM_ECCERREN bit: ITCM ECCERR enable bit of CPU1
  [5] DTCM_ECCERREN — SYSCON DTCM_ECCERREN bit: DTCM ECCERR enable bit of CPU1
  [4] SRAM2_ECCERREN — SYSCON SRAM2_ECCERREN bit: SRAM2 ECCERR enable bit of CPU1
  [3] SRAM1_ECCERREN — SYSCON SRAM1_ECCERREN bit: SRAM1 ECCERR enable bit of CPU1
  [2] FLASH_ECCERREN — SYSCON FLASH_ECCERREN bit: Flash ECCERR enable bit of CPU1
  [1] HXTLSTOPEN — SYSCON HXTLSTOPEN bit: HXTL STOP enable bit of CPU1
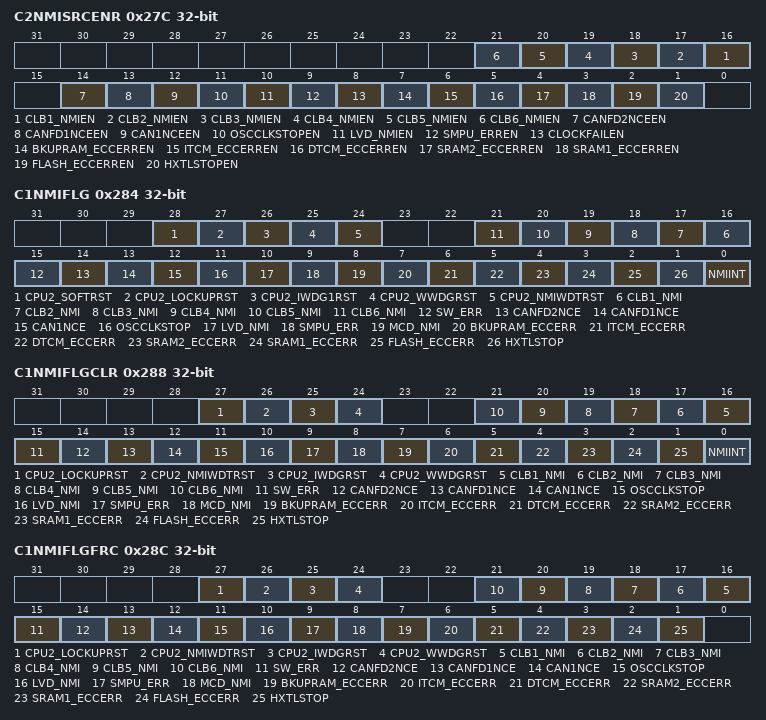
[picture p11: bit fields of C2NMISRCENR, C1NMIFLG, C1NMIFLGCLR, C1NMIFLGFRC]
0x27C C2NMISRCENR ro — SYSCON CPU2 NMI source enable read only register
  [n+15] CLB{n}_NMIEN (n=1..6) — SYSCON CLB{n}_NMIEN bit: CLB{n} NMI enable bit of CPU2
  [14] CANFD2NCEEN — SYSCON CANFD2NCEEN bit: CANFD2 NCE enable bit of CPU2
  [13] CANFD1NCEEN — SYSCON CANFD1NCEEN bit: CANFD1 NCE enable bit of CPU2
  [12] CAN1NCEEN — SYSCON CAN1NCEEN bit: CAN1 NCE enable bit of CPU2
  [11] OSCCLKSTOPEN — SYSCON OSCCLKSTOPEN bit: OSCCLK STOP enable bit of CPU2
  [10] LVD_NMIEN — SYSCON LVD_NMIEN bit: LVD NMI enable bit of CPU2
  [9] SMPU_ERREN — SYSCON SMPU_ERREN bit: SMPU ECCERR enable bit of CPU2
  [8] CLOCKFAILEN — SYSCON CLOCKFAILEN bit: CLOCKFAIL enable bit of CPU2
  [7] BKUPRAM_ECCERREN — SYSCON BKUPRAM_ECCERREN bit: BKUPRAM ECCERR enable bit of CPU2
  [6] ITCM_ECCERREN — SYSCON ITCM_ECCERREN bit: ITCM ECCERR enable bit of CPU2
  [5] DTCM_ECCERREN — SYSCON DTCM_ECCERREN bit: DTCM ECCERR enable bit of CPU2
  [4] SRAM2_ECCERREN — SYSCON SRAM2_ECCERREN bit: SRAM2 ECCERR enable bit of CPU2
  [3] SRAM1_ECCERREN — SYSCON SRAM1_ECCERREN bit: SRAM1 ECCERR enable bit of CPU2
  [2] FLASH_ECCERREN — SYSCON FLASH_ECCERREN bit: Flash ECCERR enable bit of CPU2
  [1] HXTLSTOPEN — SYSCON HXTLSTOPEN bit: HXTL STOP enable bit of CPU2
0x280 C1NMICFG ro — SYSCON CPU1 NMI configuration read only register
  [0] NMIEN — SYSCON NMIEN bit: NMI enable bit of CPU1
0x284 C1NMIFLG ro — SYSCON CPU1 NMI flag read only register
  [28] CPU2_SOFTRST — SYSCON CPU2_SOFTRST bit: CPU2 SOFT reset flag bit of CPU1
  [27] CPU2_LOCKUPRST — SYSCON CPU2_LOCKUPRST bit: CPU2 LOCKUP reset flag bit of CPU1
  [26] CPU2_IWDG1RST — SYSCON CPU2_IWDG1RST bit: CPU2 IWDG1 reset flag bit of CPU1
  [25] CPU2_WWDGRST — SYSCON CPU2_WWDGRST bit: CPU2 WWDG reset flag bit of CPU1
  [24] CPU2_NMIWDTRST — SYSCON CPU2_NMIWDTRST bit: CPU2 NMIWDT reset flag bit of CPU1
  [n+15] CLB{n}_NMI (n=1..6) — SYSCON CLB{n}_NMI bit: CLB{n} NMI flag bit of CPU1
  [15] SW_ERR — SYSCON SW_ERR bit: SW ERR flag bit of CPU1
  [14] CANFD2NCE — SYSCON CANFD2NCE bit: CANFD2 NCE flag bit of CPU1
  [13] CANFD1NCE — SYSCON CANFD1NCE bit: CANFD1 NCE flag bit of CPU1
  [12] CAN1NCE — SYSCON CAN1NCE bit: CAN1 NCE flag bit of CPU1
  [11] OSCCLKSTOP — SYSCON OSCCLKSTOP bit: OSCCLK STOP flag bit of CPU1
  [10] LVD_NMI — SYSCON LVD_NMI bit: LVD NMI flag bit of CPU1
  [9] SMPU_ERR — SYSCON SMPU_ERR bit: SMPU ECCERR flag bit of CPU1
  [8] MCD_NMI — SYSCON MCD_NMI bit: MCD NMI flag bit of CPU1
  [7] BKUPRAM_ECCERR — SYSCON BKUPRAM_ECCERR bit: BKUPRAM ECCERR flag bit of CPU1
  [6] ITCM_ECCERR — SYSCON ITCM_ECCERR bit: ITCM ECCERR flag bit of CPU1
  [5] DTCM_ECCERR — SYSCON DTCM_ECCERR bit: DTCM ECCERR flag bit of CPU1
  [4] SRAM2_ECCERR — SYSCON SRAM2_ECCERR bit: SRAM2 ECCERR flag bit of CPU1
  [3] SRAM1_ECCERR — SYSCON SRAM1_ECCERR bit: SRAM1 ECCERR flag bit of CPU1
  [2] FLASH_ECCERR — SYSCON FLASH_ECCERR bit: FLASH ECCERR flag bit of CPU1
  [1] HXTLSTOP — SYSCON HXTLSTOP bit: HXTL STOP flag bit of CPU1
  [0] NMIINT — SYSCON NMIINT bit: NMI interrupt flag bit of CPU1
0x288 C1NMIFLGCLR ro — SYSCON CPU1 NMI flag clear read only register
  [27] CPU2_LOCKUPRST — SYSCON CPU2_LOCKUPRST bit: CPU2 LOCKUP reset flag clear bit of CPU1
  [26] CPU2_NMIWDTRST — SYSCON CPU2_NMIWDTRST bit: CPU2 NMIWDT reset flag clear bit of CPU1
  [25] CPU2_IWDGRST — SYSCON CPU2_IWDGRST bit: CPU2 IWDG1 reset flag clear bit of CPU1
  [24] CPU2_WWDGRST — SYSCON CPU2_WWDGRST bit: CPU2 WWDG reset flag clear bit of CPU1
  [n+15] CLB{n}_NMI (n=1..6) — SYSCON CLB{n}_NMI bit: CLB{n} NMI flag clear bit of CPU1
  [15] SW_ERR — SYSCON SW_ERR bit: SW ERR flag clear bit of CPU1
  [14] CANFD2NCE — SYSCON CANFD2NCE bit: CANFD2 NCE flag clear bit of CPU1
  [13] CANFD1NCE — SYSCON CANFD1NCE bit: CANFD1 NCE flag clear bit of CPU1
  [12] CAN1NCE — SYSCON CAN1NCE bit: CAN1 NCE flag clear bit of CPU1
  [11] OSCCLKSTOP — SYSCON OSCCLKSTOP bit: OSCCLK STOP flag clear bit of CPU1
  [10] LVD_NMI — SYSCON LVD_NMI bit: LVD NMI flag clear bit of CPU1
  [9] SMPU_ERR — SYSCON SMPU_ERR bit: SMPU ECCERR flag clear bit of CPU1
  [8] MCD_NMI — SYSCON MCD_NMI bit: MCD NMI flag clear bit of CPU1
  [7] BKUPRAM_ECCERR — SYSCON BKUPRAM_ECCERR bit: BKUPRAM ECCERR flag clear bit of CPU1
  [6] ITCM_ECCERR — SYSCON ITCM_ECCERR bit: ITCM ECCERR flag clear bit of CPU1
  [5] DTCM_ECCERR — SYSCON DTCM_ECCERR bit: DTCM ECCERR flag clear bit of CPU1
  [4] SRAM2_ECCERR — SYSCON SRAM2_ECCERR bit: SRAM2 ECCERR flag clear bit of CPU1
  [3] SRAM1_ECCERR — SYSCON SRAM1_ECCERR bit: SRAM1 ECCERR flag clear bit of CPU1
  [2] FLASH_ECCERR — SYSCON FLASH_ECCERR bit: FLASH ECCERR flag clear bit of CPU1
  [1] HXTLSTOP — SYSCON HXTLSTOP bit: HXTL STOP flag clear bit of CPU1
  [0] NMIINT — SYSCON NMIINT bit: NMI interrupt flag clear bit of CPU1
0x28C C1NMIFLGFRC ro — SYSCON CPU1 NMI flag force read only register
  [27] CPU2_LOCKUPRST — SYSCON CPU2_LOCKUPRST bit: CPU2 LOCKUP reset flag force bit of CPU1
  [26] CPU2_NMIWDTRST — SYSCON CPU2_NMIWDTRST bit: CPU2 NMIWDT reset flag force bit of CPU1
  [25] CPU2_IWDGRST — SYSCON CPU2_IWDGRST bit: CPU2 IWDG1 reset flag force bit of CPU1
  [24] CPU2_WWDGRST — SYSCON CPU2_WWDGRST bit: CPU2 WWDG reset flag force bit of CPU1
  [n+15] CLB{n}_NMI (n=1..6) — SYSCON CLB{n}_NMI bit: CLB{n} NMI flag force bit of CPU1
  [15] SW_ERR — SYSCON SW_ERR bit: SW ERR flag force bit of CPU1
  [14] CANFD2NCE — SYSCON CANFD2NCE bit: CANFD2 NCE flag force bit of CPU1
  [13] CANFD1NCE — SYSCON CANFD1NCE bit: CANFD1 NCE flag force bit of CPU1
  [12] CAN1NCE — SYSCON CAN1NCE bit: CAN1 NCE flag force bit of CPU1
  [11] OSCCLKSTOP — SYSCON OSCCLKSTOP bit: OSCCLK STOP flag force bit of CPU1
  [10] LVD_NMI — SYSCON LVD_NMI bit: LVD NMI flag force bit of CPU1
  [9] SMPU_ERR — SYSCON SMPU_ERR bit: SMPU ECCERR flag force bit of CPU1
  [8] MCD_NMI — SYSCON MCD_NMI bit: MCD NMI flag force bit of CPU1
  [7] BKUPRAM_ECCERR — SYSCON BKUPRAM_ECCERR bit: BKUPRAM ECCERR flag force bit of CPU1
  [6] ITCM_ECCERR — SYSCON ITCM_ECCERR bit: ITCM ECCERR flag force bit of CPU1
  [5] DTCM_ECCERR — SYSCON DTCM_ECCERR bit: DTCM ECCERR flag force bit of CPU1
  [4] SRAM2_ECCERR — SYSCON SRAM2_ECCERR bit: SRAM2 ECCERR flag force bit of CPU1
  [3] SRAM1_ECCERR — SYSCON SRAM1_ECCERR bit: SRAM1 ECCERR flag force bit of CPU1
  [2] FLASH_ECCERR — SYSCON FLASH_ECCERR bit: FLASH ECCERR flag force bit of CPU1
  [1] HXTLSTOP — SYSCON HXTLSTOP bit: HXTL STOP flag force bit of CPU1
0x290 C1NMIWDGCNT ro — SYSCON CPU1 NMIWDG read only register
  [15:0] NMIWDGCNT — SYSCON NMIWDGCNT[15:0] bit: NMIWDG counter of CPU1
0x294 C1NMIWDGPRD ro — SYSCON CPU1 NMIWDG period read only register
  [15:0] NMIWDGPRD — SYSCON NMIWDGPRD[15:0] bit: NMIWDG period of CPU1
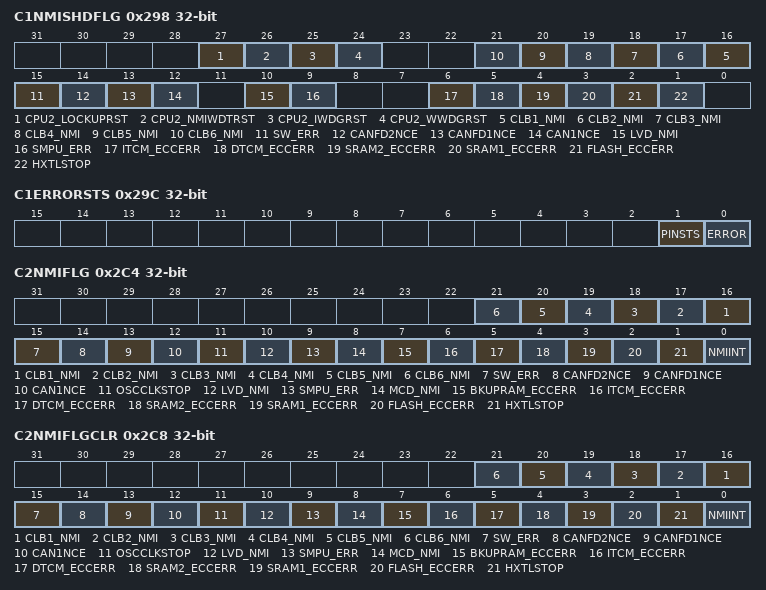
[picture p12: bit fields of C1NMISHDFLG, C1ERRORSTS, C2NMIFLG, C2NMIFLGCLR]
0x298 C1NMISHDFLG ro — SYSCON CPU1 NMI flag shadow read only register
  [27] CPU2_LOCKUPRST — SYSCON CPU2_LOCKUPRST bit: CPU2 LOCKUP reset shadow flag bit of CPU1
  [26] CPU2_NMIWDTRST — SYSCON CPU2_NMIWDTRST bit: CPU2 NMIWDT reset shadow flag bit of CPU1
  [25] CPU2_IWDGRST — SYSCON CPU2_IWDGRST bit: CPU2 IWDG reset shadow flag bit of CPU1
  [24] CPU2_WWDGRST — SYSCON CPU2_WWDGRST bit: CPU2 WWDG reset shadow flag bit of CPU1
  [n+15] CLB{n}_NMI (n=1..6) — SYSCON CLB{n}_NMI bit: CLB{n} NMI shadow flag bit of CPU1
  [15] SW_ERR — SYSCON SW_ERR bit: SW ERR shadow flag bit of CPU1
  [14] CANFD2NCE — SYSCON CANFD2NCE bit: CANFD2 NCE shadow flag bit of CPU1
  [13] CANFD1NCE — SYSCON CANFD1NCE bit: CANFD1 NCE shadow flag bit of CPU1
  [12] CAN1NCE — SYSCON CAN1NCE bit: CAN1 NCE shadow flag bit of CPU1
  [10] LVD_NMI — SYSCON LVD_NMI bit: LVD NMI shadow flag bit of CPU1
  [9] SMPU_ERR — SYSCON SMPU_ERR bit: SMPU ECCERR shadow flag bit of CPU1
  [6] ITCM_ECCERR — SYSCON ITCM_ECCERR bit: ITCM ECCERR shadow flag bit of CPU1
  [5] DTCM_ECCERR — SYSCON DTCM_ECCERR bit: DTCM ECCERR shadow flag bit of CPU1
  [4] SRAM2_ECCERR — SYSCON SRAM2_ECCERR bit: SRAM2 ECCERR shadow flag bit of CPU1
  [3] SRAM1_ECCERR — SYSCON SRAM1_ECCERR bit: SRAM1 ECCERR shadow flag bit of CPU1
  [2] FLASH_ECCERR — SYSCON FLASH_ECCERR bit: FLASH ECCERR shadow flag bit of CPU1
  [1] HXTLSTOP — SYSCON HXTLSTOP bit: HXTL STOP shadow flag bit of CPU1
0x29C C1ERRORSTS ro — SYSCON CPU1 error status register
  [1] PINSTS — SYSCON PINSTS bit: ERROR pin status bit of CPU1
  [0] ERROR — SYSCON ERROR bit: ERROR status bit of CPU1
0x2A0 C1ERRORSTSCLR ro — SYSCON CPU1 error status clear read only register
  [0] ERROR — SYSCON ERROR bit: ERROR status clear bit of CPU1
0x2A4 C1ERRORSTSFRC ro — SYSCON CPU1 error status force read only register
  [0] ERRORPOL — SYSCON ERRORPOL bit: ERRORPOL status force bit of CPU1
0x2A8 C1ERRORCTL ro — SYSCON CPU1 error status control read only register
  [0] ERRORPOL — SYSCON ERRORPOL bit: ERROR polarity select bit of CPU1
0x2AC C1ERRORLOCK ro — SYSCON CPU1 error status lock read only register
  [0] ERRORCTL — SYSCON ERRORCTL bit: ERRORCTL register lock bit of CPU1
0x2C0 C2NMICFG ro — SYSCON CPU2 NMI configuration read only register
  [0] NMIEN — SYSCON NMIEN bit: NMI enable bit of CPU2
0x2C4 C2NMIFLG ro — SYSCON CPU2 NMI flag read only register
  [n+15] CLB{n}_NMI (n=1..6) — SYSCON CLB{n}_NMI bit: CLB{n} NMI flag bit of CPU2
  [15] SW_ERR — SYSCON SW_ERR bit: SW ERR flag bit of CPU2
  [14] CANFD2NCE — SYSCON CANFD2NCE bit: CANFD2 NCE flag bit of CPU2
  [13] CANFD1NCE — SYSCON CANFD1NCE bit: CANFD1 NCE flag bit of CPU2
  [12] CAN1NCE — SYSCON CAN1NCE bit: CAN1 NCE flag bit of CPU2
  [11] OSCCLKSTOP — SYSCON OSCCLKSTOP bit: OSCCLK STOP flag bit of CPU2
  [10] LVD_NMI — SYSCON LVD_NMI bit: LVD NMI flag bit of CPU2
  [9] SMPU_ERR — SYSCON SMPU_ERR bit: SMPU ECCERR flag bit of CPU2
  [8] MCD_NMI — SYSCON MCD_NMI bit: MCD NMI flag bit of CPU2
  [7] BKUPRAM_ECCERR — SYSCON BKUPRAM_ECCERR bit: BKUPRAM ECCERR flag bit of CPU2
  [6] ITCM_ECCERR — SYSCON ITCM_ECCERR bit: ITCM ECCERR flag bit of CPU2
  [5] DTCM_ECCERR — SYSCON DTCM_ECCERR bit: DTCM ECCERR flag bit of CPU2
  [4] SRAM2_ECCERR — SYSCON SRAM2_ECCERR bit: SRAM2 ECCERR flag bit of CPU2
  [3] SRAM1_ECCERR — SYSCON SRAM1_ECCERR bit: SRAM1 ECCERR flag bit of CPU2
  [2] FLASH_ECCERR — SYSCON FLASH_ECCERR bit: FLASH ECCERR flag bit of CPU2
  [1] HXTLSTOP — SYSCON HXTLSTOP bit: HXTL STOP flag bit of CPU2
  [0] NMIINT — SYSCON NMIINT bit: NMI interrupt flag bit of CPU2
0x2C8 C2NMIFLGCLR ro — SYSCON CPU2 NMI flag clear read only register
  [n+15] CLB{n}_NMI (n=1..6) — SYSCON CLB{n}_NMI bit: CLB{n} NMI flag clear bit of CPU2
  [15] SW_ERR — SYSCON SW_ERR bit: SW ERR flag clear bit of CPU2
  [14] CANFD2NCE — SYSCON CANFD2NCE bit: CANFD2 NCE flag clear bit of CPU2
  [13] CANFD1NCE — SYSCON CANFD1NCE bit: CANFD1 NCE flag clear bit of CPU2
  [12] CAN1NCE — SYSCON CAN1NCE bit: CAN1 NCE flag clear bit of CPU2
  [11] OSCCLKSTOP — SYSCON OSCCLKSTOP bit: OSCCLK STOP flag clear bit of CPU2
  [10] LVD_NMI — SYSCON LVD_NMI bit: LVD NMI flag clear bit of CPU2
  [9] SMPU_ERR — SYSCON SMPU_ERR bit: SMPU ECCERR flag clear bit of CPU2
  [8] MCD_NMI — SYSCON MCD_NMI bit: MCD NMI flag clear bit of CPU2
  [7] BKUPRAM_ECCERR — SYSCON BKUPRAM_ECCERR bit: BKUPRAM ECCERR flag clear bit of CPU2
  [6] ITCM_ECCERR — SYSCON ITCM_ECCERR bit: ITCM ECCERR flag clear bit of CPU2
  [5] DTCM_ECCERR — SYSCON DTCM_ECCERR bit: DTCM ECCERR flag clear bit of CPU2
  [4] SRAM2_ECCERR — SYSCON SRAM2_ECCERR bit: SRAM2 ECCERR flag clear bit of CPU2
  [3] SRAM1_ECCERR — SYSCON SRAM1_ECCERR bit: SRAM1 ECCERR flag clear bit of CPU2
  [2] FLASH_ECCERR — SYSCON FLASH_ECCERR bit: FLASH ECCERR flag clear bit of CPU2
  [1] HXTLSTOP — SYSCON HXTLSTOP bit: HXTL STOP flag clear bit of CPU2
  [0] NMIINT — SYSCON NMIINT bit: NMI interrupt flag clear bit of CPU2
